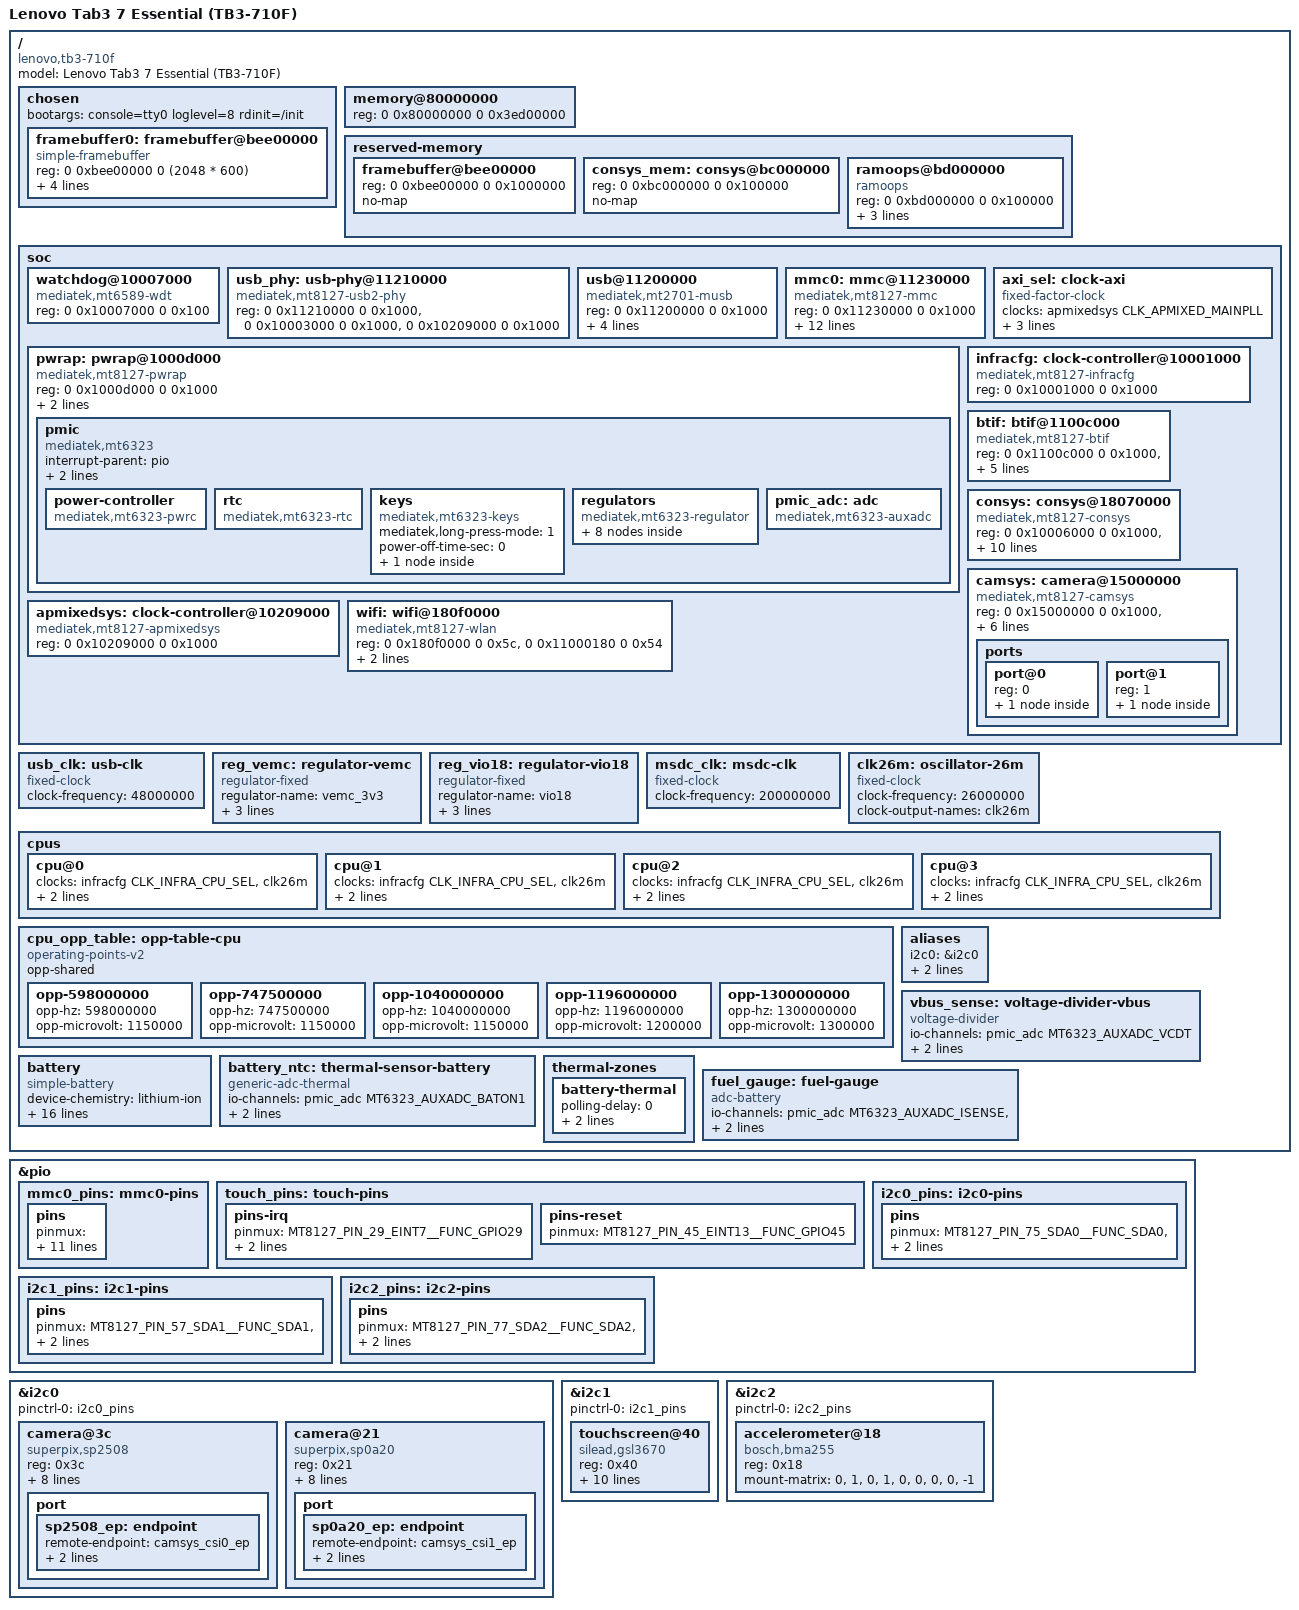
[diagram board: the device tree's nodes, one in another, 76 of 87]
// SPDX-License-Identifier: GPL-2.0
/*
 * Lenovo Tab3 7 Essential (TB3-710F), MediaTek MT8127.
 * First-boot description: everything runs on the state left by the bootloader
 * (fixed clocks, LK-initialised panel as simple-framebuffer).
 */
/dts-v1/;
#include <dt-bindings/clock/mt8127-clk.h>
#include <dt-bindings/gpio/gpio.h>
#include <dt-bindings/iio/adc/mediatek,mt6323-auxadc.h>
#include <dt-bindings/input/input.h>
#include <dt-bindings/pinctrl/mt8127-pinfunc.h>
#include "mt8127.dtsi"

/ {
	model = "Lenovo Tab3 7 Essential (TB3-710F)";
	compatible = "lenovo,tb3-710f", "mediatek,mt8127";

	chosen {
		#address-cells = <2>;
		#size-cells = <2>;
		ranges;
		bootargs = "console=tty0 loglevel=8 rdinit=/init";

		/* LK scans out 16 bpp (RGB565); the vendor kernel switches to 32 bpp later. */
		framebuffer0: framebuffer@bee00000 {
			compatible = "simple-framebuffer";
			reg = <0 0xbee00000 0 (2048 * 600)>;
			width = <1024>;
			height = <600>;
			stride = <2048>;
			format = "r5g6b5";
		};
	};

	/* System RAM ends at 0xbed00000: the rest is the TEE and the LK framebuffer. */
	memory@80000000 {
		device_type = "memory";
		reg = <0 0x80000000 0 0x3ed00000>;
	};

	reserved-memory {
		#address-cells = <2>;
		#size-cells = <2>;
		ranges;

		framebuffer@bee00000 {
			reg = <0 0xbee00000 0 0x1000000>;
			no-map;
		};

		/* Handshake and dump area shared with the CONSYS MCU, 1 MiB aligned. */
		consys_mem: consys@bc000000 {
			reg = <0 0xbc000000 0 0x100000>;
			no-map;
		};

		/* Survives a warm reset: the previous boot's log is in /sys/fs/pstore. */
		ramoops@bd000000 {
			compatible = "ramoops";
			reg = <0 0xbd000000 0 0x100000>;
			record-size = <0x20000>;
			console-size = <0x80000>;
			no-map;
		};
	};
};

/* The boot ROM chain leaves the watchdog armed; the kernel has to service it. */
/ {
	soc {
		watchdog@10007000 {
			compatible = "mediatek,mt6589-wdt";
			reg = <0 0x10007000 0 0x100>;
		};
	};
};

/*
 * USB device mode. The bootloader used the controller for fastboot; the PHY
 * driver redoes the vendor power-on sequence and ungates the USB0 clock.
 * Clocks are dummies until the MT8127 clock driver exists.
 */
/ {
	usb_clk: usb-clk {
		compatible = "fixed-clock";
		#clock-cells = <0>;
		clock-frequency = <48000000>;
	};

	soc {
		usb_phy: usb-phy@11210000 {
			compatible = "mediatek,mt8127-usb2-phy";
			reg = <0 0x11210000 0 0x1000>,	/* USB2 PHY */
			      <0 0x10003000 0 0x1000>,	/* PERICFG (clock gates) */
			      <0 0x10209000 0 0x1000>;	/* APMIXEDSYS (48 MHz) */
			#phy-cells = <0>;
		};

		usb@11200000 {
			compatible = "mediatek,mt2701-musb", "mediatek,mtk-musb";
			reg = <0 0x11200000 0 0x1000>;
			interrupts = <GIC_SPI 32 IRQ_TYPE_LEVEL_LOW>;
			interrupt-names = "mc";
			clocks = <&usb_clk>, <&usb_clk>, <&usb_clk>;
			clock-names = "main", "mcu", "univpll";
			phys = <&usb_phy>;
			dr_mode = "peripheral";
		};
	};
};

/*
 * eMMC on MSDC0. The bootloader boots from it, so pads, clock mux/gate and the
 * VEMC/VIO18 rails are already set up; the driver gets a fixed 200 MHz source clock
 * and pin states that only select the MSDC function the bootloader already uses,
 * so pad pulls and drive strength stay as they are. The MT8127 controller is the
 * MT8135-generation MSDC (no tuning/enhanced-rx features).
 *
 * Speed: high-speed single data rate at 52 MHz. DDR (the stock kernel's mode) is left
 * out on purpose: with the sampling/delay settings the bootloader leaves, multi-block
 * writes fail (CMD12 response timeouts, lost data) while reads work. 26 and 52 MHz SDR
 * pass repeated 256 MiB write/read-back checks.
 */
/ {
	/* Rails the bootloader already enabled for the eMMC (MT6323 VEMC_3V3 / VIO18). */
	reg_vemc: regulator-vemc {
		compatible = "regulator-fixed";
		regulator-name = "vemc_3v3";
		regulator-min-microvolt = <3300000>;
		regulator-max-microvolt = <3300000>;
		regulator-always-on;
	};

	reg_vio18: regulator-vio18 {
		compatible = "regulator-fixed";
		regulator-name = "vio18";
		regulator-min-microvolt = <1800000>;
		regulator-max-microvolt = <1800000>;
		regulator-always-on;
	};

	msdc_clk: msdc-clk {
		compatible = "fixed-clock";
		#clock-cells = <0>;
		clock-frequency = <200000000>;
	};

	soc {
		mmc0: mmc@11230000 {
			compatible = "mediatek,mt8127-mmc", "mediatek,mt8135-mmc";
			reg = <0 0x11230000 0 0x1000>;
			interrupts = <GIC_SPI 39 IRQ_TYPE_LEVEL_LOW>;
			clocks = <&msdc_clk>, <&msdc_clk>;
			clock-names = "source", "hclk";
			pinctrl-names = "default", "state_uhs";
			pinctrl-0 = <&mmc0_pins>;
			pinctrl-1 = <&mmc0_pins>;
			vmmc-supply = <&reg_vemc>;
			vqmmc-supply = <&reg_vio18>;
			bus-width = <8>;
			max-frequency = <52000000>;
			cap-mmc-highspeed;
			non-removable;
			no-sd;
			no-sdio;
		};
	};
};

/*
 * PMIC wrapper and the MT6323 PMIC. The preloader already initialised the
 * wrapper, and the PMIC interrupt (an EINT line) is not described yet, so only
 * the PMIC functions that need no interrupt are available.
 *
 * Only the CPU supply is constrained here, and it must stay on. Pass
 * regulator_ignore_unused on the command line: the other rails (eMMC, USB, IO)
 * were enabled by the bootloader and have no consumer in this tree yet.
 */
/ {
	clk26m: oscillator-26m {
		compatible = "fixed-clock";
		#clock-cells = <0>;
		clock-frequency = <26000000>;
		clock-output-names = "clk26m";
	};

	soc {
		pwrap: pwrap@1000d000 {
			compatible = "mediatek,mt8127-pwrap";
			reg = <0 0x1000d000 0 0x1000>;
			reg-names = "pwrap";
			interrupts = <GIC_SPI 115 IRQ_TYPE_LEVEL_HIGH>;
			clocks = <&clk26m>, <&clk26m>;
			clock-names = "spi", "wrap";

			pmic {
				compatible = "mediatek,mt6323";
				interrupt-parent = <&pio>;
				interrupts = <24 IRQ_TYPE_LEVEL_HIGH>;
				interrupt-controller;
				#interrupt-cells = <2>;

				power-controller {
					compatible = "mediatek,mt6323-pwrc";
					#power-domain-cells = <0>;
				};

				rtc {
					compatible = "mediatek,mt6323-rtc";
				};

				keys {
					compatible = "mediatek,mt6323-keys";
					mediatek,long-press-mode = <1>;
					power-off-time-sec = <0>;

					power {
						linux,keycodes = <KEY_POWER>;
						wakeup-source;
					};
				};

				regulators {
					compatible = "mediatek,mt6323-regulator";

					mt6323_vproc_reg: buck_vproc {
						regulator-name = "vproc";
						regulator-min-microvolt = <1050000>;
						regulator-max-microvolt = <1300000>;
						regulator-always-on;
						regulator-boot-on;
					};

					mt6323_vcn18_reg: ldo_vcn18 {
						regulator-name = "vcn18";
						regulator-min-microvolt = <1800000>;
						regulator-max-microvolt = <1800000>;
					};

					mt6323_vcn28_reg: ldo_vcn28 {
						regulator-name = "vcn28";
						regulator-min-microvolt = <2800000>;
						regulator-max-microvolt = <2800000>;
					};

					mt6323_vcn33_wifi_reg: ldo_vcn33_wifi {
						regulator-name = "vcn33_wifi";
						regulator-min-microvolt = <3300000>;
						regulator-max-microvolt = <3600000>;
					};

					mt6323_vcn33_bt_reg: ldo_vcn33_bt {
						regulator-name = "vcn33_bt";
						regulator-min-microvolt = <3300000>;
						regulator-max-microvolt = <3600000>;
					};

					mt6323_vcama_reg: ldo_vcama {
						regulator-name = "vcama";
						regulator-min-microvolt = <2800000>;
						regulator-max-microvolt = <2800000>;
					};

					mt6323_vcamio_reg: ldo_vcamio {
						regulator-name = "vcamio";
						regulator-min-microvolt = <1800000>;
						regulator-max-microvolt = <1800000>;
					};

					mt6323_vgp2_reg: ldo_vgp2 {
						regulator-name = "vgp2";
						regulator-min-microvolt = <2800000>;
						regulator-max-microvolt = <2800000>;
					};
				};
			};
		};
	};
};

/*
 * Clock controllers for the CPU frequency: the PLLs and the CPU clock mux. The
 * other clocks are still fixed (see the dummy clocks above).
 */
/ {
	soc {
		apmixedsys: clock-controller@10209000 {
			compatible = "mediatek,mt8127-apmixedsys";
			reg = <0 0x10209000 0 0x1000>;
			#clock-cells = <1>;
		};

		/*
		 * The bus clock: the bootloader selects MAINPLL / 4 (273 MHz) for the AXI
		 * bus, and the I2C and DMA blocks of the pericfg run from it.
		 */
		axi_sel: clock-axi {
			compatible = "fixed-factor-clock";
			clocks = <&apmixedsys CLK_APMIXED_MAINPLL>;
			#clock-cells = <0>;
			clock-mult = <1>;
			clock-div = <4>;
			clock-output-names = "axi_sel";
		};

		infracfg: clock-controller@10001000 {
			compatible = "mediatek,mt8127-infracfg", "syscon";
			reg = <0 0x10001000 0 0x1000>;
			#clock-cells = <1>;
		};
	};
};

/*
 * CPU frequency scaling. The stock operating points go from 598 MHz to 1.3 GHz;
 * the bootloader runs the CPUs at 1040 MHz and 1.15 V, which is therefore the
 * lowest voltage known to work for anything up to that frequency. The higher
 * points use the voltages of the stock tables.
 */
/ {
	cpus {
		cpu@0 {
			clocks = <&infracfg CLK_INFRA_CPU_SEL>, <&clk26m>;
			clock-names = "cpu", "intermediate";
			proc-supply = <&mt6323_vproc_reg>;
			operating-points-v2 = <&cpu_opp_table>;
		};

		cpu@1 {
			clocks = <&infracfg CLK_INFRA_CPU_SEL>, <&clk26m>;
			clock-names = "cpu", "intermediate";
			proc-supply = <&mt6323_vproc_reg>;
			operating-points-v2 = <&cpu_opp_table>;
		};

		cpu@2 {
			clocks = <&infracfg CLK_INFRA_CPU_SEL>, <&clk26m>;
			clock-names = "cpu", "intermediate";
			proc-supply = <&mt6323_vproc_reg>;
			operating-points-v2 = <&cpu_opp_table>;
		};

		cpu@3 {
			clocks = <&infracfg CLK_INFRA_CPU_SEL>, <&clk26m>;
			clock-names = "cpu", "intermediate";
			proc-supply = <&mt6323_vproc_reg>;
			operating-points-v2 = <&cpu_opp_table>;
		};
	};

	cpu_opp_table: opp-table-cpu {
		compatible = "operating-points-v2";
		opp-shared;

		opp-598000000 {
			opp-hz = /bits/ 64 <598000000>;
			opp-microvolt = <1150000>;
		};

		opp-747500000 {
			opp-hz = /bits/ 64 <747500000>;
			opp-microvolt = <1150000>;
		};

		opp-1040000000 {
			opp-hz = /bits/ 64 <1040000000>;
			opp-microvolt = <1150000>;
		};

		opp-1196000000 {
			opp-hz = /bits/ 64 <1196000000>;
			opp-microvolt = <1200000>;
		};

		opp-1300000000 {
			opp-hz = /bits/ 64 <1300000000>;
			opp-microvolt = <1300000>;
		};
	};
};

/*
 * The I2C pins already carry the I2C function when the kernel starts; the
 * states below keep it explicit. The on-board pull-ups are used.
 */
&pio {
	mmc0_pins: mmc0-pins {
		pins {
			pinmux = <MT8127_PIN_127_MSDC0_DAT7__FUNC_MSDC0_DAT7>,
				 <MT8127_PIN_128_MSDC0_DAT6__FUNC_MSDC0_DAT6>,
				 <MT8127_PIN_129_MSDC0_DAT5__FUNC_MSDC0_DAT5>,
				 <MT8127_PIN_130_MSDC0_DAT4__FUNC_MSDC0_DAT4>,
				 <MT8127_PIN_131_MSDC0_RSTB__FUNC_MSDC0_RSTB>,
				 <MT8127_PIN_132_MSDC0_CMD__FUNC_MSDC0_CMD>,
				 <MT8127_PIN_133_MSDC0_CLK__FUNC_MSDC0_CLK>,
				 <MT8127_PIN_134_MSDC0_DAT3__FUNC_MSDC0_DAT3>,
				 <MT8127_PIN_135_MSDC0_DAT2__FUNC_MSDC0_DAT2>,
				 <MT8127_PIN_136_MSDC0_DAT1__FUNC_MSDC0_DAT1>,
				 <MT8127_PIN_137_MSDC0_DAT0__FUNC_MSDC0_DAT0>;
		};
	};

	touch_pins: touch-pins {
		pins-irq {
			pinmux = <MT8127_PIN_29_EINT7__FUNC_GPIO29>;
			bias-pull-up;
			input-enable;
		};

		pins-reset {
			pinmux = <MT8127_PIN_45_EINT13__FUNC_GPIO45>;
		};
	};

	i2c0_pins: i2c0-pins {
		pins {
			pinmux = <MT8127_PIN_75_SDA0__FUNC_SDA0>,
				 <MT8127_PIN_76_SCL0__FUNC_SCL0>;
			bias-disable;
		};
	};

	i2c1_pins: i2c1-pins {
		pins {
			pinmux = <MT8127_PIN_57_SDA1__FUNC_SDA1>,
				 <MT8127_PIN_58_SCL1__FUNC_SCL1>;
			bias-disable;
		};
	};

	i2c2_pins: i2c2-pins {
		pins {
			pinmux = <MT8127_PIN_77_SDA2__FUNC_SDA2>,
				 <MT8127_PIN_78_SCL2__FUNC_SCL2>;
			bias-disable;
		};
	};
};

/ {
	aliases {
		i2c0 = &i2c0;
		i2c1 = &i2c1;
		i2c2 = &i2c2;
	};
};

/* The camera sensors, probed by the stock kernel at 0x3c (rear) and 0x21 (front), and the lens driver at 0x18. */
&i2c0 {
	pinctrl-names = "default";
	pinctrl-0 = <&i2c0_pins>;
	status = "okay";
};

&i2c1 {
	pinctrl-names = "default";
	pinctrl-0 = <&i2c1_pins>;
	status = "okay";

	/*
	 * The sizes are the extents of the sensor in the units the firmware reports
	 * (not pixels): the long axis is horizontal on the landscape display. The
	 * reset (power) line is held low by the bootloader until the driver releases
	 * it.
	 */
	touchscreen@40 {
		compatible = "silead,gsl3670";
		reg = <0x40>;
		pinctrl-names = "default";
		pinctrl-0 = <&touch_pins>;
		interrupt-parent = <&pio>;
		interrupts = <7 IRQ_TYPE_EDGE_RISING>;
		power-gpios = <&pio 45 GPIO_ACTIVE_HIGH>;
		avdd-supply = <&mt6323_vgp2_reg>;
		firmware-name = "gsl3670-tb3-710f.fw";
		touchscreen-size-x = <1672>;
		touchscreen-size-y = <903>;
		touchscreen-inverted-y;
		silead,max-fingers = <5>;
	};
};

&i2c2 {
	pinctrl-names = "default";
	pinctrl-0 = <&i2c2_pins>;
	status = "okay";

	/*
	 * The stock kernel polls the accelerometer, so no interrupt is described. The
	 * mount matrix is the stock orientation 5: x' = y, y' = x, z' = -z.
	 */
	accelerometer@18 {
		compatible = "bosch,bma255";
		reg = <0x18>;
		mount-matrix = "0", "1", "0",
			       "1", "0", "0",
			       "0", "0", "-1";
	};
};

/*
 * Connectivity subsystem (WiFi, BT): the BTIF link and the CONSYS platform block. Both nodes
 * describe hardware for the out-of-tree mt8127-consys drivers, which define their bindings.
 */
/ {
	soc {
		btif: btif@1100c000 {
			compatible = "mediatek,mt8127-btif";
			reg = <0 0x1100c000 0 0x1000>,
			      <0 0x11000780 0 0x80>,
			      <0 0x11000800 0 0x80>;
			reg-names = "btif", "tx_dma", "rx_dma";
			interrupts = <GIC_SPI 50 IRQ_TYPE_LEVEL_LOW>,
				     <GIC_SPI 71 IRQ_TYPE_LEVEL_LOW>,
				     <GIC_SPI 72 IRQ_TYPE_LEVEL_LOW>;
			interrupt-names = "btif", "tx_dma", "rx_dma";
			clocks = <&pericfg CLK_PERI_AP_DMA>;
			clock-names = "apdma";
		};

		/* The memory-mapped host interface of the WiFi function inside CONSYS. */
		wifi: wifi@180f0000 {
			compatible = "mediatek,mt8127-wlan";
			reg = <0 0x180f0000 0 0x5c>,
			      <0 0x11000180 0 0x54>;
			reg-names = "hif", "apdma-hif";
			interrupts = <GIC_SPI 184 IRQ_TYPE_LEVEL_LOW>;
			clocks = <&pericfg CLK_PERI_AP_DMA>;
			clock-names = "apdma";
		};

		consys: consys@18070000 {
			compatible = "mediatek,mt8127-consys";
			reg = <0 0x10006000 0 0x1000>,
			      <0 0x18070000 0 0x200>;
			reg-names = "spm", "mcu-config";
			mediatek,infracfg = <&infracfg>;
			interrupts = <GIC_SPI 185 IRQ_TYPE_LEVEL_LOW>,
				     <GIC_SPI 184 IRQ_TYPE_LEVEL_LOW>,
				     <GIC_SPI 163 IRQ_TYPE_LEVEL_LOW>;
			interrupt-names = "bgf", "wifi", "watchdog";
			memory-region = <&consys_mem>;
			vcn18-supply = <&mt6323_vcn18_reg>;
			vcn28-supply = <&mt6323_vcn28_reg>;
			vcn33-wifi-supply = <&mt6323_vcn33_wifi_reg>;
			vcn33-bt-supply = <&mt6323_vcn33_bt_reg>;
		};
	};
};

/* Camera subsystem: sensor interface, ISP pass 1 and the two CSI-2 inputs (rear on port 0, front on port 1). */
/ {
	soc {
		camsys: camera@15000000 {
			compatible = "mediatek,mt8127-camsys";
			reg = <0 0x15000000 0 0x1000>,
			      <0 0x15004000 0 0x4000>,
			      <0 0x15008000 0 0x1000>,
			      <0 0x1500c000 0 0x1000>,
			      <0 0x10010800 0 0x100>,
			      <0 0x10006000 0 0x1000>,
			      <0 0x10000000 0 0x1000>,
			      <0 0x10005000 0 0x1000>;
			reg-names = "imgsys", "isp", "seninf", "mipi-rx",
				    "mipi-ana", "spm", "topckgen", "gpio";
			interrupts = <GIC_SPI 143 IRQ_TYPE_LEVEL_LOW>;
			#clock-cells = <0>;

			ports {
				#address-cells = <1>;
				#size-cells = <0>;

				port@0 {
					reg = <0>;
					camsys_csi0_ep: endpoint {
						remote-endpoint = <&sp2508_ep>;
						data-lanes = <1>;
					};
				};

				port@1 {
					reg = <1>;
					camsys_csi1_ep: endpoint {
						remote-endpoint = <&sp0a20_ep>;
						data-lanes = <1>;
					};
				};
			};
		};
	};
};

&i2c0 {
	camera@3c {
		compatible = "superpix,sp2508";
		reg = <0x3c>;
		clocks = <&camsys>;
		clock-names = "xclk";
		clock-frequency = <24000000>;
		avdd-supply = <&mt6323_vcama_reg>;
		dovdd-supply = <&mt6323_vcamio_reg>;
		reset-gpios = <&pio 53 GPIO_ACTIVE_LOW>;
		powerdown-gpios = <&pio 56 GPIO_ACTIVE_HIGH>;
		orientation = <1>;
		rotation = <0>;

		port {
			sp2508_ep: endpoint {
				remote-endpoint = <&camsys_csi0_ep>;
				data-lanes = <1>;
				link-frequencies = /bits/ 64 <300000000>;
			};
		};
	};

	camera@21 {
		compatible = "superpix,sp0a20";
		reg = <0x21>;
		clocks = <&camsys>;
		clock-names = "xclk";
		clock-frequency = <24000000>;
		avdd-supply = <&mt6323_vcama_reg>;
		dovdd-supply = <&mt6323_vcamio_reg>;
		reset-gpios = <&pio 55 GPIO_ACTIVE_LOW>;
		powerdown-gpios = <&pio 54 GPIO_ACTIVE_HIGH>;
		orientation = <0>;
		rotation = <0>;

		port {
			sp0a20_ep: endpoint {
				remote-endpoint = <&camsys_csi1_ep>;
				data-lanes = <1>;
				link-frequencies = /bits/ 64 <104000000>;
			};
		};
	};
};

/*
 * The MT6323 auxiliary ADC. VCDT sees VBUS through a 330k/39k divider.
 */
&pwrap {
	pmic {
		pmic_adc: adc {
			compatible = "mediatek,mt6323-auxadc";
			#io-channel-cells = <1>;
		};
	};
};

/ {
	vbus_sense: voltage-divider-vbus {
		compatible = "voltage-divider";
		io-channels = <&pmic_adc MT6323_AUXADC_VCDT>;
		#io-channel-cells = <1>;
		output-ohms = <39000>;
		full-ohms = <369000>;
	};
};

/*
 * Battery. There is no fuel gauge or current sense resistor: the PMIC ADC measures
 * the battery voltage on ISENSE (BATSNS is on the system rail of the charger power
 * path) and the battery NTC on BATON1 (10k, pulled up to 1.8 V through 16.9k, 30k in
 * parallel). The capacity is derived from the voltage alone.
 *
 * The design capacity is the smaller of the two stock gauge capacities at 25 degrees
 * Celsius. The open circuit voltage tables are the stock gauge profiles of the first
 * battery supplier, at -10, 0, 25 and 50 degrees Celsius. The charge parameters are
 * the stock ones.
 */
/ {
	battery: battery {
		compatible = "simple-battery";
		device-chemistry = "lithium-ion";
		charge-full-design-microamp-hours = <3515000>;
		voltage-min-design-microvolt = <3400000>;
		voltage-max-design-microvolt = <4352000>;
		precharge-current-microamp = <128000>;
		charge-term-current-microamp = <128000>;
		constant-charge-current-max-microamp = <960000>;
		constant-charge-voltage-max-microvolt = <4352000>;
		ocv-capacity-celsius = <(-10) 0 25 50>;
		ocv-capacity-table-0 = <4333000 100  4308000 98  4287000 97  4269000 95
					4249000 94  4232000 92  4214000 91  4197000 89
					4180000 87  4163000 86  4145000 84  4129000 83
					4113000 81  4096000 80  4080000 78  4064000 76
					4048000 75  4031000 73  4012000 72  3993000 70
					3976000 69  3962000 67  3948000 66  3934000 64
					3921000 62  3909000 61  3897000 59  3885000 58
					3875000 56  3865000 55  3856000 53  3847000 51
					3839000 50  3831000 48  3824000 47  3816000 45
					3811000 44  3804000 42  3799000 41  3793000 39
					3788000 38  3783000 36  3778000 34  3773000 33
					3770000 31  3766000 30  3763000 28  3758000 27
					3754000 25  3748000 24  3741000 22  3733000 21
					3724000 19  3714000 17  3705000 16  3699000 14
					3693000 13  3688000 11  3683000 10  3678000 8
					3668000 7  3641000 5  3596000 4  3560000 3
					3549000 2  3543000 2  3538000 2  3533000 1
					3527000 1  3522000 1  3516000 1  3510000 0
					3504000 0  3498000 0  3400000 0>;
		ocv-capacity-table-1 = <4337000 100  4315000 98  4296000 97  4279000 95
					4261000 94  4243000 92  4226000 91  4209000 89
					4192000 88  4175000 86  4158000 85  4142000 83
					4125000 81  4110000 80  4094000 78  4078000 77
					4064000 75  4048000 74  4031000 72  4015000 71
					3998000 69  3982000 67  3969000 66  3954000 64
					3940000 63  3926000 61  3913000 60  3900000 58
					3889000 57  3878000 55  3868000 54  3860000 52
					3851000 50  3844000 49  3837000 47  3829000 46
					3823000 44  3817000 43  3812000 41  3807000 40
					3801000 38  3796000 37  3792000 35  3787000 33
					3784000 32  3779000 30  3776000 29  3773000 27
					3769000 26  3765000 24  3759000 23  3752000 21
					3742000 19  3732000 18  3720000 16  3711000 15
					3704000 13  3700000 12  3697000 10  3692000 9
					3688000 7  3680000 6  3655000 4  3606000 2
					3545000 1  3448000 0  3400000 0>;
		ocv-capacity-table-2 = <4333000 100  4312000 98  4294000 97  4276000 95
					4258000 94  4241000 92  4224000 91  4207000 89
					4190000 88  4174000 86  4157000 85  4141000 83
					4126000 82  4110000 80  4095000 79  4080000 77
					4065000 76  4051000 74  4037000 73  4022000 71
					4009000 70  3996000 68  3984000 67  3972000 65
					3963000 64  3951000 62  3940000 61  3928000 59
					3913000 58  3897000 56  3881000 55  3867000 53
					3856000 52  3846000 50  3838000 49  3830000 47
					3824000 46  3818000 44  3811000 43  3806000 41
					3801000 40  3797000 38  3792000 37  3787000 35
					3784000 34  3780000 32  3776000 31  3773000 29
					3771000 28  3768000 26  3764000 25  3760000 23
					3753000 22  3748000 20  3741000 19  3733000 17
					3721000 16  3710000 14  3695000 13  3687000 11
					3684000 10  3682000 8  3680000 7  3676000 5
					3663000 4  3605000 2  3513000 1  3400000 0>;
		ocv-capacity-table-3 = <4323000 100  4301000 98  4282000 97  4265000 95
					4247000 94  4230000 92  4213000 91  4195000 89
					4179000 88  4163000 86  4147000 85  4130000 83
					4115000 82  4098000 80  4083000 79  4067000 77
					4052000 76  4038000 74  4024000 73  4010000 71
					3997000 70  3984000 68  3971000 67  3962000 65
					3950000 64  3939000 62  3929000 61  3918000 59
					3906000 58  3892000 56  3874000 55  3857000 53
					3846000 51  3837000 50  3828000 48  3821000 47
					3814000 45  3808000 44  3802000 42  3796000 41
					3790000 39  3786000 38  3780000 36  3776000 35
					3772000 33  3768000 32  3765000 30  3759000 29
					3749000 27  3741000 26  3737000 24  3731000 23
					3725000 21  3718000 20  3711000 18  3703000 17
					3689000 15  3676000 14  3663000 12  3659000 11
					3658000 9  3656000 8  3651000 6  3643000 5
					3597000 3  3521000 2  3400000 0>;
	};

	/* NTC voltage to temperature, from the stock 10k thermistor table and divider. */
	battery_ntc: thermal-sensor-battery {
		compatible = "generic-adc-thermal";
		#thermal-sensor-cells = <0>;
		#io-channel-cells = <0>;
		io-channels = <&pmic_adc MT6323_AUXADC_BATON1>;
		io-channel-names = "sensor-channel";
		temperature-lookup-table = <
			(-20000) 997
			(-15000) 961
			(-10000) 921
			(-5000) 876
			0 827
			5000 774
			10000 720
			15000 664
			20000 608
			25000 553
			30000 500
			35000 450
			40000 403
			45000 359
			50000 320
			55000 283
			60000 251>;
	};

	thermal-zones {
		battery-thermal {
			polling-delay = <0>;
			polling-delay-passive = <0>;
			thermal-sensors = <&battery_ntc>;
		};
	};

	fuel_gauge: fuel-gauge {
		compatible = "adc-battery";
		io-channels = <&pmic_adc MT6323_AUXADC_ISENSE>, <&battery_ntc>;
		io-channel-names = "voltage", "temperature";
		monitored-battery = <&battery>;
	};
};
